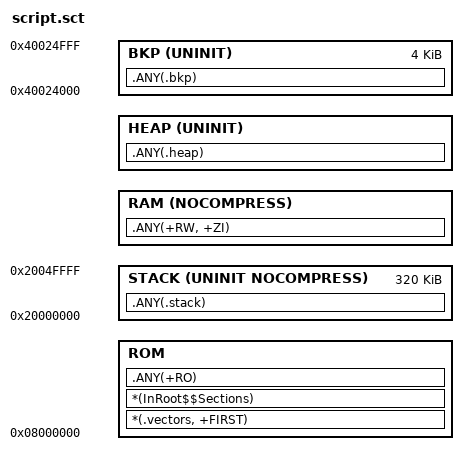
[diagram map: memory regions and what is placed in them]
/*******************************************************************************
@file     stm32f7xx.sct
@author   Rajmund Szymanski
@date     21.05.2016
@brief    Scatter file for STM32F746NG device with 1024KB FLASH and 320KB RAM
*******************************************************************************/

FLASH 0x08000000 0x00100000
{
	ROM +0
	{
		*(.vectors, +FIRST)
		*(InRoot$$Sections)
		.ANY(+RO)
	}

	BKP 0x40024000 UNINIT 0x00001000
	{
		.ANY(.bkp)
	}

	STACK 0x20000000 UNINIT NOCOMPRESS 0x00050000
	{
		.ANY(.stack)
	}

	RAM ALIGNEXPR(+0, 8) NOCOMPRESS
	{
		.ANY(+RW, +ZI)
	}

	HEAP ALIGNEXPR(+0, 8) UNINIT
	{
		.ANY(.heap)
	}
}
